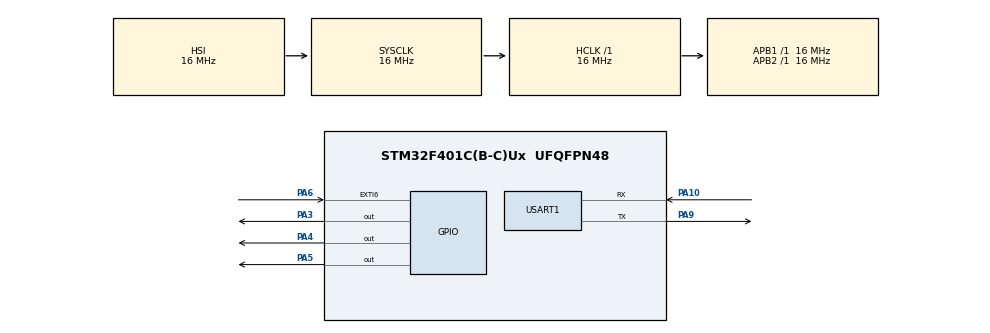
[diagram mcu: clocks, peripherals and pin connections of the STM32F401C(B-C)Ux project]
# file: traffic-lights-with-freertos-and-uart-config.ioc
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Dma.Request0=USART1_RX
Dma.USART1_RX.0.Direction=DMA_PERIPH_TO_MEMORY
Dma.USART1_RX.0.FIFOMode=DMA_FIFOMODE_DISABLE
Dma.USART1_RX.0.Instance=DMA2_Stream2
Dma.USART1_RX.0.MemDataAlignment=DMA_MDATAALIGN_BYTE
Dma.USART1_RX.0.MemInc=DMA_MINC_ENABLE
Dma.USART1_RX.0.Mode=DMA_NORMAL
Dma.USART1_RX.0.PeriphDataAlignment=DMA_PDATAALIGN_BYTE
Dma.USART1_RX.0.PeriphInc=DMA_PINC_DISABLE
Dma.USART1_RX.0.Priority=DMA_PRIORITY_LOW
FREERTOS.Tasks01=defaultTask,24,128,StartDefaultTask,Default,NULL,Dynamic,NULL,NULL
Mcu.Family=STM32F4
Mcu.Name=STM32F401C(B-C)Ux
Mcu.Package=UFQFPN48
NVIC.DMA2_Stream2_IRQn=true\:5\:0\:false\:false\:true\:true\:false\:true\:true
NVIC.PriorityGroup=NVIC_PRIORITYGROUP_4
NVIC.TIM1_UP_TIM10_IRQn=true\:0\:0\:true\:false\:true\:false\:false\:true\:true
NVIC.TimeBase=TIM1_UP_TIM10_IRQn
NVIC.TimeBaseIP=TIM1
NVIC.USART1_IRQn=true\:5\:0\:false\:false\:true\:true\:true\:true\:true
PA10.Mode=Asynchronous
PA10.Signal=USART1_RX
PA3.Signal=GPIO_Output
PA4.Signal=GPIO_Output
PA5.Signal=GPIO_Output
PA6.GPIO_ModeDefaultEXTI=GPIO_MODE_IT_FALLING
PA6.Signal=GPXTI6
PA9.Mode=Asynchronous
PA9.Signal=USART1_TX
ProjectManager.HeapSize=0x200
ProjectManager.StackSize=0x400
ProjectManager.TargetToolchain=STM32CubeIDE
RCC.AHBFreq_Value=16000000
RCC.APB1Freq_Value=16000000
RCC.APB2Freq_Value=16000000
RCC.CortexFreq_Value=16000000
RCC.HSE_VALUE=25000000
RCC.HSI_VALUE=16000000
RCC.LSE_VALUE=32768
RCC.SYSCLKFreq_VALUE=16000000
RCC.VCOOutputFreq_Value=192000000
USART1.VirtualMode=VM_ASYNC
VP_FREERTOS_VS_CMSIS_V2.Mode=CMSIS_V2
VP_SYS_VS_tim1.Mode=TIM1
board=custom

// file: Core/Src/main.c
/* USER CODE BEGIN Header */
/**
  ******************************************************************************
  * @file           : main.c
  * @brief          : Main program body
  ******************************************************************************
  * @attention
  *
  * Copyright (c) 2026 STMicroelectronics.
  * All rights reserved.
  *
  * This software is licensed under terms that can be found in the LICENSE file
  * in the root directory of this software component.
  * If no LICENSE file comes with this software, it is provided AS-IS.
  *
  ******************************************************************************
  */
/* USER CODE END Header */
#include "main.h"
#include "cmsis_os.h"

/* USER CODE BEGIN Includes */
#include "logger.h"
#include "command_handling.h"
#include "traffic-lights.h"
/* USER CODE END Includes */

UART_HandleTypeDef huart1;
DMA_HandleTypeDef hdma_usart1_rx;

void SystemClock_Config(void);
static void MX_GPIO_Init(void);
static void MX_DMA_Init(void);
static void MX_USART1_UART_Init(void);

int main(void)
{

  /* MCU Configuration--------------------------------------------------------*/

  /* Reset of all peripherals, Initializes the Flash interface and the Systick. */
  HAL_Init();

  /* Configure the system clock */
  SystemClock_Config();

  /* Initialize all configured peripherals */
  MX_GPIO_Init();
  MX_DMA_Init();
  MX_USART1_UART_Init();

  /* Infinite loop */
  /* USER CODE BEGIN WHILE */

  logger_init(&huart1);

  QueueHandle_t command_queue = NULL;

  pins_config_t pins_config = {
	  .gpio_port = GPIOA,
	  .green_light_pin = 3,
	  .yellow_light_pin = 4,
	  .red_light_pin = 5
  };

  traffic_lights_init(&command_queue, &pins_config);
  init_command_handler(&huart1, command_queue);

  vTaskStartScheduler();

  while (1)
  {
    /* USER CODE END WHILE */

  }
}

void SystemClock_Config(void)
{
  RCC_OscInitTypeDef RCC_OscInitStruct = {0};
  RCC_ClkInitTypeDef RCC_ClkInitStruct = {0};

  /** Configure the main internal regulator output voltage
  */
  __HAL_RCC_PWR_CLK_ENABLE();
  __HAL_PWR_VOLTAGESCALING_CONFIG(PWR_REGULATOR_VOLTAGE_SCALE2);

  /** Initializes the RCC Oscillators according to the specified parameters
  * in the RCC_OscInitTypeDef structure.
  */
  RCC_OscInitStruct.OscillatorType = RCC_OSCILLATORTYPE_HSI;
  RCC_OscInitStruct.HSIState = RCC_HSI_ON;
  RCC_OscInitStruct.HSICalibrationValue = RCC_HSICALIBRATION_DEFAULT;
  RCC_OscInitStruct.PLL.PLLState = RCC_PLL_NONE;
  if (HAL_RCC_OscConfig(&RCC_OscInitStruct) != HAL_OK)
  {
    Error_Handler();
  }

  /** Initializes the CPU, AHB and APB buses clocks
  */
  RCC_ClkInitStruct.ClockType = RCC_CLOCKTYPE_HCLK|RCC_CLOCKTYPE_SYSCLK
                              |RCC_CLOCKTYPE_PCLK1|RCC_CLOCKTYPE_PCLK2;
  RCC_ClkInitStruct.SYSCLKSource = RCC_SYSCLKSOURCE_HSI;
  RCC_ClkInitStruct.AHBCLKDivider = RCC_SYSCLK_DIV1;
  RCC_ClkInitStruct.APB1CLKDivider = RCC_HCLK_DIV1;
  RCC_ClkInitStruct.APB2CLKDivider = RCC_HCLK_DIV1;

  if (HAL_RCC_ClockConfig(&RCC_ClkInitStruct, FLASH_LATENCY_0) != HAL_OK)
  {
    Error_Handler();
  }
}

static void MX_USART1_UART_Init(void)
{

  huart1.Instance = USART1;
  huart1.Init.BaudRate = 115200;
  huart1.Init.WordLength = UART_WORDLENGTH_8B;
  huart1.Init.StopBits = UART_STOPBITS_1;
  huart1.Init.Parity = UART_PARITY_NONE;
  huart1.Init.Mode = UART_MODE_TX_RX;
  huart1.Init.HwFlowCtl = UART_HWCONTROL_NONE;
  huart1.Init.OverSampling = UART_OVERSAMPLING_16;
  if (HAL_UART_Init(&huart1) != HAL_OK)
  {
    Error_Handler();
  }

}

static void MX_DMA_Init(void)
{

  /* DMA controller clock enable */
  __HAL_RCC_DMA2_CLK_ENABLE();

  /* DMA interrupt init */
  /* DMA2_Stream2_IRQn interrupt configuration */
  HAL_NVIC_SetPriority(DMA2_Stream2_IRQn, 5, 0);
  HAL_NVIC_EnableIRQ(DMA2_Stream2_IRQn);

}

static void MX_GPIO_Init(void)
{
  GPIO_InitTypeDef GPIO_InitStruct = {0};

  /* GPIO Ports Clock Enable */
  __HAL_RCC_GPIOA_CLK_ENABLE();

  /*Configure GPIO pin Output Level */
  HAL_GPIO_WritePin(GPIOA, GPIO_PIN_3|GPIO_PIN_4|GPIO_PIN_5, GPIO_PIN_RESET);

  /*Configure GPIO pins : PA3 PA4 PA5 */
  GPIO_InitStruct.Pin = GPIO_PIN_3|GPIO_PIN_4|GPIO_PIN_5;
  GPIO_InitStruct.Mode = GPIO_MODE_OUTPUT_PP;
  GPIO_InitStruct.Pull = GPIO_NOPULL;
  GPIO_InitStruct.Speed = GPIO_SPEED_FREQ_LOW;
  HAL_GPIO_Init(GPIOA, &GPIO_InitStruct);

  /*Configure GPIO pin : PA6 */
  GPIO_InitStruct.Pin = GPIO_PIN_6;
  GPIO_InitStruct.Mode = GPIO_MODE_IT_FALLING;
  GPIO_InitStruct.Pull = GPIO_NOPULL;
  HAL_GPIO_Init(GPIOA, &GPIO_InitStruct);

}

void HAL_TIM_PeriodElapsedCallback(TIM_HandleTypeDef *htim)
{
  if (htim->Instance == TIM1)
  {
    HAL_IncTick();
  }
}

void Error_Handler(void)
{
  __disable_irq();
  while (1)
  {
  }
}
